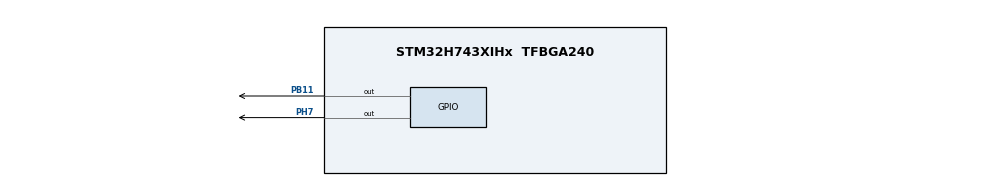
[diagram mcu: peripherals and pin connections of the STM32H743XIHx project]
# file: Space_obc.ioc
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IWDG1.Prescaler=IWDG_PRESCALER_32
IWDG1.Reload=1999
Mcu.Family=STM32H7
Mcu.Name=STM32H743XIHx
Mcu.Package=TFBGA240
NVIC.PriorityGroup=NVIC_PRIORITYGROUP_4
PB11.Signal=GPIO_Output
PH7.Signal=GPIO_Output
ProjectManager.HeapSize=0x200
ProjectManager.StackSize=0x400
ProjectManager.TargetToolchain=STM32CubeIDE
RCC.ADCFreq_Value=129000000
RCC.APB1Freq_Value=64000000
RCC.APB2Freq_Value=64000000
RCC.APB3Freq_Value=64000000
RCC.APB4Freq_Value=64000000
RCC.CortexFreq_Value=64000000
RCC.HCLKFreq_Value=64000000
RCC.SYSCLKFreq_VALUE=64000000
RCC.USBFreq_Value=129000000
VP_IWDG1_VS_IWDG.Mode=IWDG_Activate
VP_MEMORYMAP_VS_MEMORYMAP.Mode=CurAppReg
board=custom

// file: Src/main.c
/* USER CODE BEGIN Header */
/**
  ******************************************************************************
  * @file           : main.c
  * @brief          : Main program body
  ******************************************************************************
  * @attention
  *
  * Copyright (c) 2026 STMicroelectronics.
  * All rights reserved.
  *
  * This software is licensed under terms that can be found in the LICENSE file
  * in the root directory of this software component.
  * If no LICENSE file comes with this software, it is provided AS-IS.
  *
  ******************************************************************************
  */
/* USER CODE END Header */
#include "main.h"

/* USER CODE BEGIN Includes */
#include <string.h>
/* USER CODE END Includes */

/* USER CODE BEGIN PTD */
typedef struct __attribute__((aligned(32))) {
    uint32_t magic;            /* valid-block sentinel                */
    uint32_t active_mode;      /* mission-critical state (dummy here) */
    uint32_t fault_counter;    /* mission-critical state (dummy here) */
    uint32_t wdg_reset_count;  /* this is what we increment & watch   */
    uint32_t reset_cause;      /* RCC reset flag snapshot             */
    uint32_t _pad[3];          /* pad to exactly 32 bytes             */
} PersistentState;
/* USER CODE END PTD */

/* USER CODE BEGIN PD */
#define PERSIST_ADDR     0x08100000UL   /* Bank 2, Sector 0 — clear of your code */
#define PERSIST_SECTOR   FLASH_SECTOR_0
#define PERSIST_BANK     FLASH_BANK_2
#define PERSIST_MAGIC    0xC0FFEE00UL    /* sentinel: tells us the block is valid */
/* USER CODE END PD */

IWDG_HandleTypeDef hiwdg1;

void SystemClock_Config(void);
static void MX_GPIO_Init(void);
static void MX_IWDG1_Init(void);

/* USER CODE BEGIN 0 */
/* Read the 32-byte block straight out of flash (flash is memory-mapped). */
static void flash_load(PersistentState *s)
{
    memcpy(s, (const void *)PERSIST_ADDR, sizeof(PersistentState));
}

/* Erase the sector and write the 32-byte block back. */
static HAL_StatusTypeDef flash_save(PersistentState *s)
{
    HAL_StatusTypeDef st;
    FLASH_EraseInitTypeDef er = {0};
    uint32_t sector_err = 0;

    s->magic = PERSIST_MAGIC;

    HAL_FLASH_Unlock();

    er.TypeErase    = FLASH_TYPEERASE_SECTORS;
    er.Banks        = PERSIST_BANK;
    er.Sector       = PERSIST_SECTOR;
    er.NbSectors    = 1;
    er.VoltageRange = FLASH_VOLTAGE_RANGE_3;

    st = HAL_FLASHEx_Erase(&er, &sector_err);
    if (st != HAL_OK) { HAL_FLASH_Lock(); return st; }

    /* H7 programs one 256-bit (32-byte) flash word; arg is the SOURCE address. */
    st = HAL_FLASH_Program(FLASH_TYPEPROGRAM_FLASHWORD,
                           PERSIST_ADDR, (uint32_t)(uintptr_t)s);

    HAL_FLASH_Lock();
    return st;
}

/* Blink PH7 n times, slowly enough to count by eye / on camera. */
static void blink_count(uint32_t n)
{
    for (uint32_t k = 0; k < n; k++)
    {
        HAL_GPIO_WritePin(GPIOH, GPIO_PIN_7, GPIO_PIN_SET);
        HAL_Delay(100);
        HAL_GPIO_WritePin(GPIOH, GPIO_PIN_7, GPIO_PIN_RESET);
        HAL_Delay(100);
    }
}
/* USER CODE END 0 */

int main(void)
{

  /* MCU Configuration--------------------------------------------------------*/

  /* Reset of all peripherals, Initializes the Flash interface and the Systick. */
  HAL_Init();

  /* Configure the system clock */
  SystemClock_Config();

  /* Initialize all configured peripherals */
  MX_GPIO_Init();
  // MX_IWDG1_Init();
  /* USER CODE BEGIN 2 */
  /* --- T-OBC-06: non-volatile state across reset --- */
    PersistentState ps;
    flash_load(&ps);

    if (ps.magic != PERSIST_MAGIC)
    {
        /* First ever boot (or sector erased): initialise the block. */
        ps.active_mode     = 1;        /* e.g. NOMINAL */
        ps.fault_counter   = 0;
        ps.wdg_reset_count = 0;
        ps.reset_cause     = 0;
    }

    /* Snapshot what caused THIS boot's reset (your existing IWDG check, generalised). */
    if (__HAL_RCC_GET_FLAG(RCC_FLAG_IWDG1RST)) ps.reset_cause = 1;       /* watchdog */
    else if (__HAL_RCC_GET_FLAG(RCC_FLAG_PINRST)) ps.reset_cause = 2;    /* NRST pin */
    else ps.reset_cause = 3;                                            /* other    */
    __HAL_RCC_CLEAR_RESET_FLAGS();

    /* EVIDENCE: blink the count that was RETAINED from the previous boot. */
    HAL_Delay(500);                 /* small gap so the first blink is clean */
    blink_count(ps.wdg_reset_count);

    /* Now increment and persist for next boot, then save. */
    ps.wdg_reset_count++;
    ps.fault_counter++;             /* bump a second field too, to show multi-field retention */
    flash_save(&ps);

  /* USER CODE END 2 */

  /* Infinite loop */
  while (1)
  {

  }
}

void SystemClock_Config(void)
{
  RCC_OscInitTypeDef RCC_OscInitStruct = {0};
  RCC_ClkInitTypeDef RCC_ClkInitStruct = {0};

  /** Supply configuration update enable
  */
  HAL_PWREx_ConfigSupply(PWR_LDO_SUPPLY);

  /** Configure the main internal regulator output voltage
  */
  __HAL_PWR_VOLTAGESCALING_CONFIG(PWR_REGULATOR_VOLTAGE_SCALE3);

  while(!__HAL_PWR_GET_FLAG(PWR_FLAG_VOSRDY)) {}

  /** Initializes the RCC Oscillators according to the specified parameters
  * in the RCC_OscInitTypeDef structure.
  */
  RCC_OscInitStruct.OscillatorType = RCC_OSCILLATORTYPE_HSI|RCC_OSCILLATORTYPE_LSI;
  RCC_OscInitStruct.HSIState = RCC_HSI_DIV1;
  RCC_OscInitStruct.HSICalibrationValue = RCC_HSICALIBRATION_DEFAULT;
  RCC_OscInitStruct.LSIState = RCC_LSI_ON;
  RCC_OscInitStruct.PLL.PLLState = RCC_PLL_NONE;
  if (HAL_RCC_OscConfig(&RCC_OscInitStruct) != HAL_OK)
  {
    Error_Handler();
  }

  /** Initializes the CPU, AHB and APB buses clocks
  */
  RCC_ClkInitStruct.ClockType = RCC_CLOCKTYPE_HCLK|RCC_CLOCKTYPE_SYSCLK
                              |RCC_CLOCKTYPE_PCLK1|RCC_CLOCKTYPE_PCLK2
                              |RCC_CLOCKTYPE_D3PCLK1|RCC_CLOCKTYPE_D1PCLK1;
  RCC_ClkInitStruct.SYSCLKSource = RCC_SYSCLKSOURCE_HSI;
  RCC_ClkInitStruct.SYSCLKDivider = RCC_SYSCLK_DIV1;
  RCC_ClkInitStruct.AHBCLKDivider = RCC_HCLK_DIV1;
  RCC_ClkInitStruct.APB3CLKDivider = RCC_APB3_DIV1;
  RCC_ClkInitStruct.APB1CLKDivider = RCC_APB1_DIV1;
  RCC_ClkInitStruct.APB2CLKDivider = RCC_APB2_DIV1;
  RCC_ClkInitStruct.APB4CLKDivider = RCC_APB4_DIV1;

  if (HAL_RCC_ClockConfig(&RCC_ClkInitStruct, FLASH_LATENCY_1) != HAL_OK)
  {
    Error_Handler();
  }
}

static void MX_IWDG1_Init(void)
{

  hiwdg1.Instance = IWDG1;
  hiwdg1.Init.Prescaler = IWDG_PRESCALER_32;
  hiwdg1.Init.Window = 4095;
  hiwdg1.Init.Reload = 1999;
  if (HAL_IWDG_Init(&hiwdg1) != HAL_OK)
  {
    Error_Handler();
  }

}

static void MX_GPIO_Init(void)
{
  GPIO_InitTypeDef GPIO_InitStruct = {0};

  /* GPIO Ports Clock Enable */
  __HAL_RCC_GPIOB_CLK_ENABLE();
  __HAL_RCC_GPIOH_CLK_ENABLE();

  /*Configure GPIO pin Output Level */
  HAL_GPIO_WritePin(GPIOB, GPIO_PIN_11, GPIO_PIN_RESET);

  /*Configure GPIO pin Output Level */
  HAL_GPIO_WritePin(GPIOH, GPIO_PIN_7, GPIO_PIN_RESET);

  /*Configure GPIO pin : PB11 */
  GPIO_InitStruct.Pin = GPIO_PIN_11;
  GPIO_InitStruct.Mode = GPIO_MODE_OUTPUT_PP;
  GPIO_InitStruct.Pull = GPIO_NOPULL;
  GPIO_InitStruct.Speed = GPIO_SPEED_FREQ_LOW;
  HAL_GPIO_Init(GPIOB, &GPIO_InitStruct);

  /*Configure GPIO pin : PH7 */
  GPIO_InitStruct.Pin = GPIO_PIN_7;
  GPIO_InitStruct.Mode = GPIO_MODE_OUTPUT_PP;
  GPIO_InitStruct.Pull = GPIO_NOPULL;
  GPIO_InitStruct.Speed = GPIO_SPEED_FREQ_LOW;
  HAL_GPIO_Init(GPIOH, &GPIO_InitStruct);

}

void Error_Handler(void)
{
  __disable_irq();
  while (1)
  {
  }
}
